# f29h85x_wadi_config_regs register map
Vendor: Texas Instruments
Peripheral module from a debugger description file (folder C29).
Registers are 32-bit, read-write, no defined reset value unless marked. A register's access mark holds for its fields unless they carry their own. Offsets are as the file gives them; lines under a group give offsets from that group; [hi:lo] are bit positions; {n}, {i} and the like mark numbered series; 'fields as' and 'values as' point back to an identical list; <NAME> marks a mode.

## WADI_CONFIG_REGS — WADI CONFIG Registers
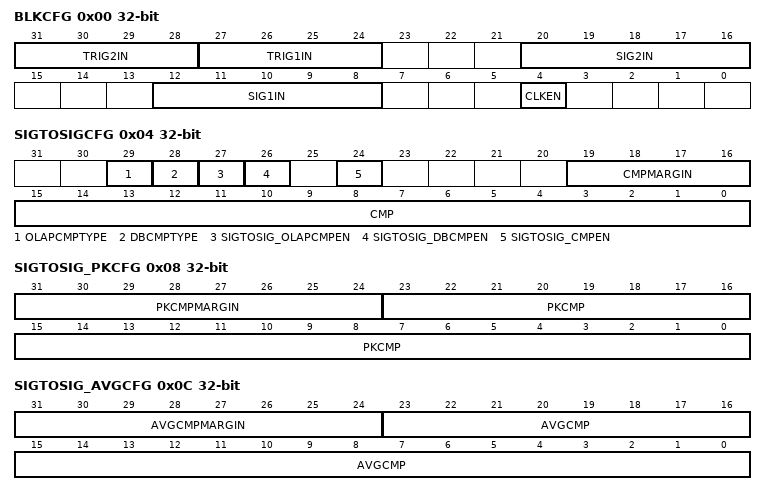
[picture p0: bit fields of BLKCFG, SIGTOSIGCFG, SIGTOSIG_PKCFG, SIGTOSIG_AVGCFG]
0x00 BLKCFG — WADI Block Clock Divider
  [31:28] TRIG2IN — Selects trigger input signal for SIG2 analysis
  [27:24] TRIG1IN — Selects trigger input signal for SIG1 analysis
  [20:16] SIG2IN — Selects the input signal for the SIG2 input of WADI block
  [12:8] SIG1IN — Selects the input signal for the SIG1 input of WADI block
  [4] CLKEN — Enables clock for WADI block
0x04 SIGTOSIGCFG — Configuration for SIG1 to SIG2 comparison for WADI Block
  [29] OLAPCMPTYPE — Selects the check type for overlap control
  [28] DBCMPTYPE — Selects the check type for deadband control
  [27] SIGTOSIG_OLAPCMPEN — Enables the overlap check between two signals
  [26] SIGTOSIG_DBCMPEN — Enables the deadband check between two signals
  [24] SIGTOSIG_CMPEN — Enables the signal to signal compare
  [19:16] CMPMARGIN — Margin of error for difference of width/sum measurement
  [15:0] CMP — Compare value for difference of width/sum measurement
0x08 SIGTOSIG_PKCFG — Signal1 to Signal2 peak comparison value and margin for WADI Block
  [31:24] PKCMPMARGIN — Margin of error for difference of peak measurement
  [23:0] PKCMP — Compare value for difference of peak measurement
0x0C SIGTOSIG_AVGCFG — Signal1 to Signal2 average comparison value and margin for WADI Block
  [31:24] AVGCMPMARGIN — Margin for difference of average of both signals
  [23:0] AVGCMP — Compare difference for measurements average of both signals
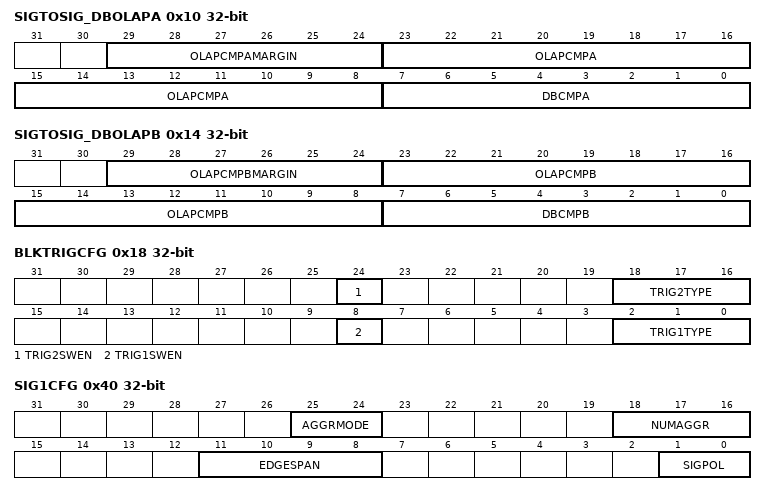
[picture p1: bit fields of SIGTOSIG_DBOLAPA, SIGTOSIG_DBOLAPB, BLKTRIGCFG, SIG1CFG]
0x10 SIGTOSIG_DBOLAPA — Signal1 to Signal2 dead-band comparison difference and margin for WADI Block
  [29:24] OLAPCMPAMARGIN — Margin of variation of overlap between both signals
  [23:8] OLAPCMPA — Compare value for Overlap between both signal levels
  [7:0] DBCMPA — Compare value for dead-band between both signals
0x14 SIGTOSIG_DBOLAPB — Signal1 to Signal2 dead-band and Overlap compare values for WADI Block
  [29:24] OLAPCMPBMARGIN — Margin of variation of overlap between both signals
  [23:8] OLAPCMPB — Compare value for Overlap between both signal levels
  [7:0] DBCMPB — Compare value for dead-band between both signals
0x18 BLKTRIGCFG — The trigger configuration for SIG1 and SIG2 of the WADI Block
  [24] TRIG2SWEN — Software trigger for the SIG2
  [18:16] TRIG2TYPE — The trigger type for SIG2 signal input.
  [8] TRIG1SWEN — Software trigger for the SIG1
  [2:0] TRIG1TYPE — The trigger type for SIG1 signal input.
0x40 SIG1CFG — Measurement configuration for SIG1 of WADI Block
  [25:24] AGGRMODE — Whether peak or average or both measurements to compute
  [18:16] NUMAGGR — Defines number of measurements to be aggregated
  [11:8] EDGESPAN — Defines span of edges of given type to measure the width.
  [1:0] SIGPOL — Starting edge select as rise, fall or either
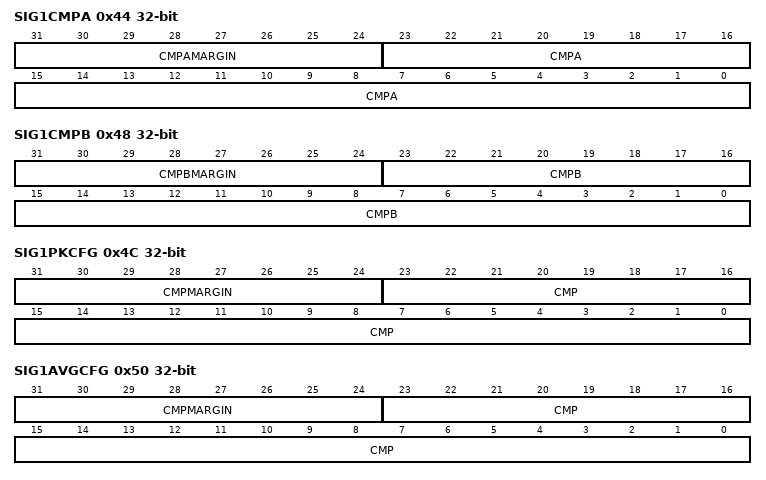
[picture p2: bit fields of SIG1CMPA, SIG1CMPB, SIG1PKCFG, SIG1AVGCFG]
0x44 SIG1CMPA — Envelope-1 compare value and margin for SIG1 for WADI Block
  [31:24] CMPAMARGIN — +/- Margin for compare-1 around SIG1CMPA[CMPA]
  [23:0] CMPA — Compare A value for measured count of the SIG1
0x48 SIG1CMPB — Envelope-2 compare value and margin for SIG1 for WADI Block
  [31:24] CMPBMARGIN — +/- Margin for compare B around SIG1CMPB[CMPB]
  [23:0] CMPB — Compare B value for measured count of the SIG1
0x4C SIG1PKCFG — Peak of the aggregation compare configuration for SIG1 of WADI Block
  [31:24] CMPMARGIN — Margin of variation for peak measurements of SIG1
  [23:0] CMP — Compare value for peak measurements of SIG1
0x50 SIG1AVGCFG — Average of the aggregation comparison configuration for SIG1 of WADI Block
  [31:24] CMPMARGIN — Margin for average of measurements of SIG1
  [23:0] CMP — Compare value for average of measurements of SIG1
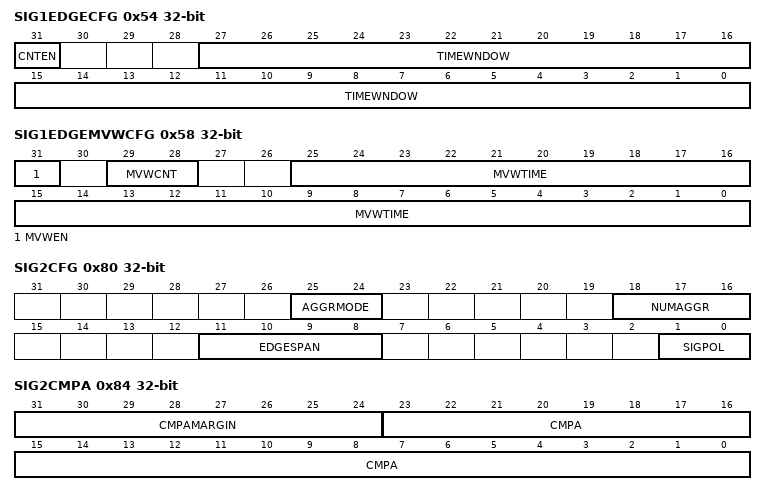
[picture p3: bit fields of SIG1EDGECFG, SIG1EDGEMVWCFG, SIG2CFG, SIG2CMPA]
0x54 SIG1EDGECFG — Frequency measurement configuration for SIG1 of WADI Block
  [31] CNTEN — SIG1 Edge count mode enable
  [27:0] TIMEWNDOW — Time window to count edges of SIG1
0x58 SIG1EDGEMVWCFG — Moving Window Configuration for SIG1 of WADI Block
  [31] MVWEN — Moving window operation enable
  [29:28] MVWCNT — Moving window count:number of MWVTIME windows to accumulate
  [25:0] MVWTIME — Moving Window time
0x80 SIG2CFG — Measurement configuration for SIG2 of WADI Block
  fields as SIG1CFG
0x84 SIG2CMPA — Compare value A and +/- margin for SIG2 for WADI Block
  [31:24] CMPAMARGIN — +/- Margin for compare-1 around SIG2CMPA[CMPA]
  [23:0] CMPA — Compare A value for measured count of the SIG2
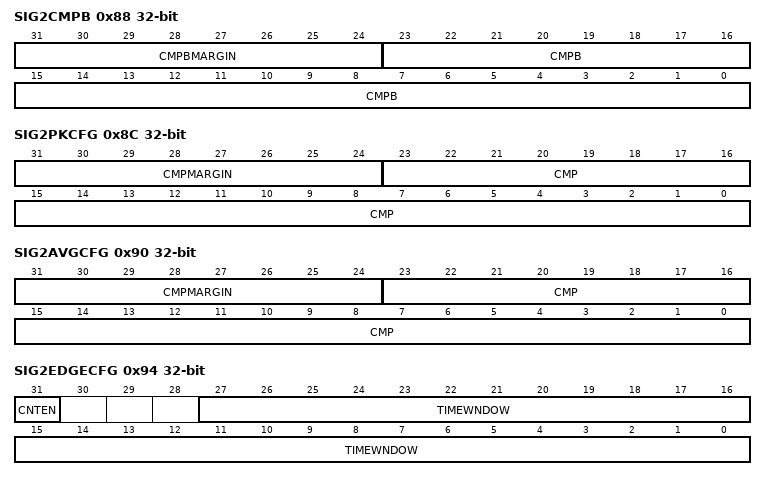
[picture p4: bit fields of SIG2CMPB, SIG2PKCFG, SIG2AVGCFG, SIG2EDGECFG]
0x88 SIG2CMPB — Compare value B and +/- margin for SIG2 for WADI Block
  [31:24] CMPBMARGIN — +/- Margin for compare B around SIG2CMPB[CMPB]
  [23:0] CMPB — Compare B value for measured count of the SIG2
0x8C SIG2PKCFG — Peak of the aggregation compare configuration for SIG2 of WADI Block
  [31:24] CMPMARGIN — Margin of variation for peak measurements of SIG2
  [23:0] CMP — Compare value for peak measurements of SIG2
0x90 SIG2AVGCFG — Average of the aggregation comparison configuration for SIG2 of WADI Block
  [31:24] CMPMARGIN — Margin for average of measurements of SIG2
  [23:0] CMP — Compare value for average of measurements of SIG2
0x94 SIG2EDGECFG — Frequency measurement configuration for SIG2 of WADI Block
  [31] CNTEN — SIG2 Edge count mode enable
  [27:0] TIMEWNDOW — Time window to count edges of SIG2
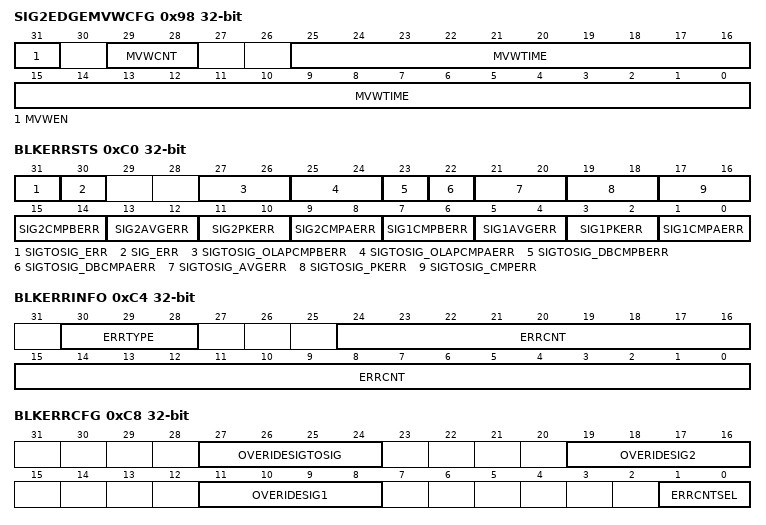
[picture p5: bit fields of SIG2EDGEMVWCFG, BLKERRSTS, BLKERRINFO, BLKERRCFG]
0x98 SIG2EDGEMVWCFG — Moving Window Configuration for SIG2 of WADI Block
  fields as SIG1EDGEMVWCFG
0xC0 BLKERRSTS — Block status register
  [31] SIGTOSIG_ERR — Mismatch in number of readings between signals
  [30] SIG_ERR — Measurement error of unexpected waveform anomaly
  [27:26] SIGTOSIG_OLAPCMPBERR — Overlap check Compare B error of SIGTOSIG measurements
  [25:24] SIGTOSIG_OLAPCMPAERR — Overlap check Compare A error of SIGTOSIG measurements
  [23] SIGTOSIG_DBCMPBERR — Deadband Compare B Error for the SIGTOSIG measurements
  [22] SIGTOSIG_DBCMPAERR — Deadband Compare A error for the SIGTOSIG measurements
  [21:20] SIGTOSIG_AVGERR — Average error for the SIGTOSIG measurements difference
  [19:18] SIGTOSIG_PKERR — Error of SIGTOSIG peak measurements difference
  [17:16] SIGTOSIG_CMPERR — Compare error for the SIGTOSIG measurements difference
  [15:14] SIG2CMPBERR — Compare B margin error for the SIG2 measurements
  [13:12] SIG2AVGERR — Average of aggregation error for the SIG2 measurements
  [11:10] SIG2PKERR — Error of SIG2 peak measurements
  [9:8] SIG2CMPAERR — Compare A margin error for the SIG2 measurements
  [7:6] SIG1CMPBERR — Compare B margin error for the SIG1 measurements
  [5:4] SIG1AVGERR — Average of aggregation error for the SIG1 measurements
  [3:2] SIG1PKERR — Error of SIG1 peak measurements
  [1:0] SIG1CMPAERR — Compare A margin error for the SIG1 measurements
0xC4 BLKERRINFO ro — Block count value of failed register
  [30:28] ERRTYPE — Type of error of the registered count
  [24:0] ERRCNT — First failed count of SIGx multiplexed to this register
0xC8 BLKERRCFG — Block Debug additional info.
  [27:24] OVERIDESIGTOSIG — Drives the correction to both signals if SIGTOSIG error
  [19:16] OVERIDESIG2 — Drives the signal correction for outputting the SIG2
  [11:8] OVERIDESIG1 — Drives the signal correction for outputting the SIG1
  [1:0] ERRCNTSEL — Selects the count to be multiplexed for debug
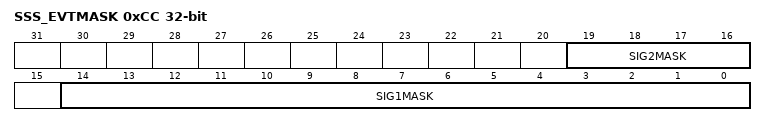
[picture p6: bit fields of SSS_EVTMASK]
0xCC SSS_EVTMASK — Mask to combine Block errors for trigger of SSS in event word Output by WADI block
  [19:16] SIG2MASK — Mask for specific WADI events to SSS event word or not
  [14:0] SIG1MASK — Mask for specific WADI events to SSS event word or not
0xE8 PARTEST — Enables parity test
  [3:0] TESTEN — Parity test enable configuration
